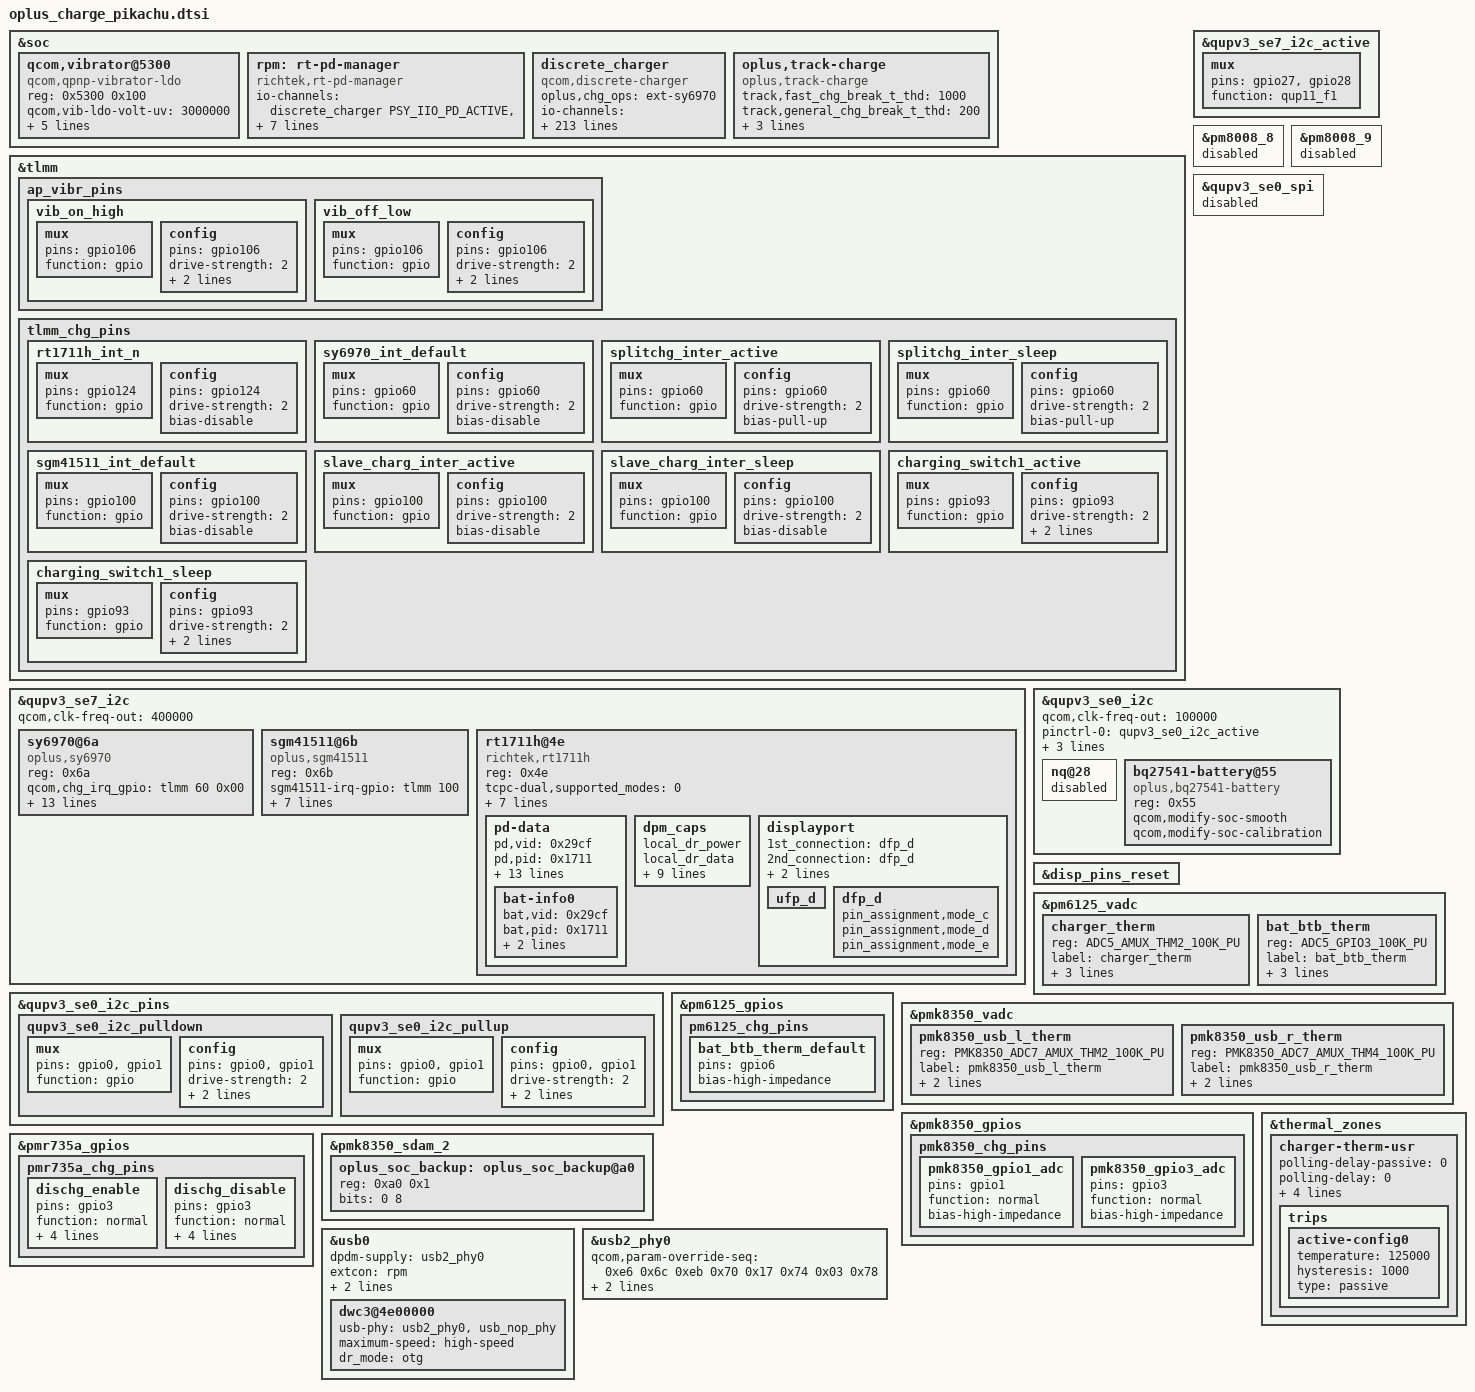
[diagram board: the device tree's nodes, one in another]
#include <dt-bindings/spmi/spmi.h>
#include <dt-bindings/iio/qcom,spmi-vadc.h>
#include <dt-bindings/iio/qti_power_supply_iio.h>

&soc {
	qcom,vibrator@5300 {
		compatible = "qcom,qpnp-vibrator-ldo";
		reg = <0x5300 0x100>;
		qcom,vib-ldo-volt-uv = <3000000>;
		qcom,disable-overdrive;
		qcom,vib-type = <1>;	/*0:ldo 1:gpio*/
		status = "okay";

		qcom,vibrator_switch-gpio = <&tlmm 106 0x00>;
		pinctrl-names = "vib_on_high", "vib_off_low";
		pinctrl-0 = <&vib_on_high>;
		pinctrl-1 = <&vib_off_low >;
	};
};

&tlmm {
	ap_vibr_pins: ap_vibr_pins{
		vib_on_high: vib_on_high{
			mux {
				pins = "gpio106";
				function = "gpio";
			};

			config {
				pins = "gpio106";
				drive-strength = <2>;
				bias-disable;
				output-high;
			};
		};

		vib_off_low: vib_off_low{
			mux {
				pins = "gpio106";
				function = "gpio";
			};

			config {
				pins = "gpio106";
				drive-strength = <2>;
				bias-disable;
				output-high;
			};
		};
	};
};


/* Main charger, slave charger, CC logic I2C */
&qupv3_se7_i2c_active {
        mux {
                pins = "gpio27", "gpio28";
                function = "qup11_f1";
        };
};

&qupv3_se7_i2c {
	status = "okay";
	qcom,clk-freq-out = <400000>;

	sy6970@6a {
		status = "okay";
		compatible = "oplus,sy6970";
		reg = <0x6a>; /*The device operates as a slave device with address 6AH*/

		qcom,chg_irq_gpio = <&tlmm 60 0x00>;
		dpdm-supply = <&usb2_phy0>;
		pinctrl-names = "default",
					"splitchg_inter_active",
					"splitchg_inter_sleep";

		pinctrl-0 = <&sy6970_int_default>;
		pinctrl-1 = <&splitchg_inter_active>;
		pinctrl-2 = <&splitchg_inter_sleep>;

		ti,sy6970,usb-vlim =<4400>;
		ti,sy6970,usb-vreg = <4400>;
		ti,sy6970,usb-ichg = <500>;
		ti,sy6970,precharge-current = <256>;
		ti,sy6970,termination-current = <320>;
		ti,sy6970,charge-detect-enable;
		ti,sy6970,boost-voltage = <5100>;
		ti,sy6970,boost-current = <1400>;

		/*
		 * Charger name
		 * Main charger: primary_chg
		 * Slave charger: secondary_chg
		 */
		charger_name = "primary_chg";
	};

	sgm41511@6b {
        compatible = "oplus,sgm41511";
        reg = <0x6b>; /*The device operates as a slave device with address 6BH*/
		status = "okay";

        sgm41511-irq-gpio = <&tlmm 100 0x00>;
	qcom,set_sgm41511_ovp = <10500>;	/*mv*/
		pinctrl-names = "default",
					"slave_charg_inter_active",
					"slave_charg_inter_sleep",
					"charging_switch1_active",
					"charging_switch1_sleep";
		pinctrl-0 = <&sgm41511_int_default>;
		pinctrl-1 = <&slave_charg_inter_active>;
		pinctrl-2 = <&slave_charg_inter_sleep>;
		pinctrl-3 = <&charging_switch1_active>;
		pinctrl-4 = <&charging_switch1_sleep>;

		/*Pikachu Used as MOS control grid for auxiliary charging and slow power on*/
		qcom,slave_charg_enable-gpio = <&tlmm 93 0x00>;
        };

	rt1711h@4e {
		compatible = "richtek,rt1711h";
		reg = <0x4e>;
		status = "okay";
		tcpc-dual,supported_modes = <0>; /* 0: dfp/ufp, */
						 /* 1: dfp, 2: ufp */
		rt-tcpc,name = "type_c_port0"; /* tcpc_device's name */
		rt-tcpc,role_def = <1>; /* 0: Unknown, 1: SNK, 2: SRC */
					/* 3: DRP, 4: Try.SRC, 5: Try.SNK */
		rt-tcpc,rp_level = <0>; /* 0: Default, 1: 1.5, 2: 3.0 */
		rt-tcpc,vconn_supply  = <1>;  /* 0: Never, 1: Always, */
					      /* 2: EMarkOnly, 3: StartOnly */
		/* rt-tcpc,disable_pe; */
		rt1711pd,intr_gpio = <&tlmm 124 0x0>;
		rt1711pd,intr_gpio_num = <124>;
		pinctrl-names = "default";
		pinctrl-0 = <&rt1711h_int_n>;
		pd-data {
			pd,vid = <0x29cf>;
			pd,pid = <0x1711>;
			pd,source-cap-ext = <0x171129cf 0x00000000 0x00000000
					     0x00000000 0x00000000 0x02000000>;
			pd,mfrs = "RichtekTCPC";

			/*
			 *	VSAFE5V = 0, MAX_POWER = 1, CUSTOM = 2,
			 *	MAX_POWER_LV = 0x21, MAX_POWER_LVIC = 0x31
			 *	MAX_POWER_HV = 0x41, MAX_POWER_HVIC = 0x51
			 */
			pd,charging_policy= <0x31>;

			/*
			 * Fixed 5V, 500 mA <0x00019032>
			 * Fixed 5V, 1A <0x00019064>
			 * Fixed 5V, 2A <0x000190c8>
			 * Fixed 5V, 3A <0x0001912c>
			 * Fixed 9V, 500 mA <0x0002d032>
			 * Fixed 9V, 1A <0x0002d064>
			 * Fixed 9V, 2A <0x0002d0c8>
			 * Fixed 9V, 3A <0x0002d12c>
			 * Variable 5-9V, 1A <0x8642d064>
			 * Variable 5-9V, 2A <0x8642d0c8>
			 * Variable 5-9V, 3A <0x8642d12c>
			 * PPS 3V~5.9V, 3A <0xC0761E3C>
			 */
			pd,source-pdo-size = <1>;
			pd,source-pdo-data = <0x00019032>;
			pd,sink-pdo-size = <1>;
			pd,sink-pdo-data = <0x000190c8>;

			/*
			 * No DP, host + device
			 *	pd,id-vdo-size = <6>;
			 *	pd,id-vdo-data = <0xd14029cf 0x0 0x17110000
						  0x41800000 0x0 0x21800000>;
			 * With DP
			 *	pd,id-vdo-size = <6>;
			 *	pd,id-vdo-data = <0xd54029cf 0x0 0x17110000
						  0x41800000 0x0 0x21800000>;
			 */

			pd,id-vdo-size = <6>;
			pd,id-vdo-data = <0xd14029cf 0x0 0x17110000
					  0x41800000 0x0 0x21800000>;

			bat,nr = <1>;
			pd,country_nr = <0>;

			bat-info0 {
				bat,vid = <0x29cf>;
				bat,pid = <0x1711>;
				bat,mfrs = "bat1";
				bat,design_cap = <3000>;
			};

			//bat-info1 {
			//	bat,vid = <0x8abc>;
			//	bat,pid = <0x5234>;
			//	bat,mfrs = "bat2";
			//	bat,design_cap = <4000>;
			//};

			//country0 {
			//	pd,country_code = <0x5457>;
			//	pd,country_len = <2>; /* max len = 26 */
			//	pd,country_data = <0xff 0xff>;
			//};

			//country1 {
			//	pd,country_code = <0x5553>;
			//	pd,country_len = <3>; /* max len = 26 */
			//	pd,country_data = <0xf1 0xf2 0xf3>;
			//};
		};
		dpm_caps {
			local_dr_power;
			local_dr_data;
			//local_ext_power;
			local_usb_comm;
			//local_usb_suspend;
			//local_high_cap;
			//local_give_back;
			local_no_suspend;
			local_vconn_supply;

			//attemp_discover_cable_dfp;
			attemp_enter_dp_mode;
			attemp_discover_cable;
			attemp_discover_id;
			attemp_discover_svid;

			/* 0: disable, 1: prefer_snk, 2: prefer_src */
			pr_check = <0>;
			//pr_reject_as_source;
			//pr_reject_as_sink;
			//pr_check_gp_source;
			//pr_check_gp_sink;

			/* 0: disable, 1: prefer_ufp, 2: prefer_dfp */
			dr_check = <0>;
			//dr_reject_as_dfp;
			//dr_reject_as_ufp;
		};
		displayport {
			/* connection type = "both", "ufp_d", "dfp_d" */
			1st_connection = "dfp_d";
			2nd_connection = "dfp_d";
			signal,dp_v13;
			//signal,dp_gen2;
			//usbr20_not_used;
			typec,receptacle;
			ufp_d {
				//pin_assignment,mode_a;
				//pin_assignment,mode_b;
				//pin_assignment,mode_c;
				//pin_assignment,mode_d;
				//pin_assignment,mode_e;
			};
			dfp_d {
				//pin_assignment,mode_a;
				//pin_assignment,mode_b;
				pin_assignment,mode_c;
				pin_assignment,mode_d;
				pin_assignment,mode_e;
				//pin_assignment,mode_f;
			};
		};
	};
};

&soc {
	rpm: rt-pd-manager {
		compatible = "richtek,rt-pd-manager";
		#io-channel-cells = <1>;
		io-channels = <&discrete_charger PSY_IIO_PD_ACTIVE>,
			      <&discrete_charger PSY_IIO_PD_USB_SUSPEND_SUPPORTED>,
			      <&discrete_charger PSY_IIO_PD_IN_HARD_RESET>,
			      <&discrete_charger PSY_IIO_PD_CURRENT_MAX>,
			      <&discrete_charger PSY_IIO_PD_VOLTAGE_MIN>,
			      <&discrete_charger PSY_IIO_PD_VOLTAGE_MAX>,
			      <&discrete_charger PSY_IIO_USB_REAL_TYPE>,
			      <&discrete_charger PSY_IIO_PD_SDP>;
		io-channel-names = "pd_active",
				   "pd_usb_suspend_supported",
				   "pd_in_hard_reset",
				   "pd_current_max",
				   "pd_voltage_min",
				   "pd_voltage_max",
				   "real_type",
				   "pd_sdp";
	};
};

&pm8008_8 {
	status = "disabled";
};

&pm8008_9 {
	status = "disabled";
};

&tlmm {
	tlmm_chg_pins: tlmm_chg_pins {
		rt1711h_int_n: rt1711h_int_n {
			mux {
				pins = "gpio124";
				function = "gpio";
			};

			config {
				pins = "gpio124";
				drive-strength = <2>;
				bias-disable;
			};
		};

		/*SY6970*/
		sy6970_int_default: sy6970_int_default {
			mux {
				pins = "gpio60";
				function = "gpio";
			};
			config {
				pins = "gpio60";
				drive-strength = <2>;
				bias-disable;
			};
		};

		/*split_chg*/
		splitchg_inter_active: splitchg_inter_active {
			mux {
				pins = "gpio60";
				function = "gpio";
			};
			config {
				pins = "gpio60";
				drive-strength = <2>;
				bias-pull-up;
			};
		};

		splitchg_inter_sleep: splitchg_inter_sleep {
			mux {
				pins = "gpio60";
				function = "gpio";
			};
			config {
				pins = "gpio60";
				drive-strength = <2>;
				bias-pull-up;
			};
		};

		/*SGM41511*/
		sgm41511_int_default: sgm41511_int_default {
			mux {
				pins = "gpio100";
				function = "gpio";
			};

			config {
				pins = "gpio100";
				drive-strength = <2>;
				bias-disable; /* NO PULL */
			};
		};
		slave_charg_inter_active: slave_charg_inter_active {
			mux {
				pins = "gpio100";
				function = "gpio";
			};

			config {
				pins = "gpio100";
				drive-strength = <2>;
				bias-disable; /* NO PULL */
			};
		};

		slave_charg_inter_sleep: slave_charg_inter_sleep {
			mux {
				pins = "gpio100";
				function = "gpio";
			};

			config {
				pins = "gpio100";
				drive-strength = <2>;
				bias-disable; /* NO PULL */
			};
		};

		charging_switch1_active: charging_switch1_active {
			mux {
				pins = "gpio93";
				function = "gpio";
			};

			config {
				pins = "gpio93";
				drive-strength = <2>;
				bias-disable;
				output-high;
			};
		};

		charging_switch1_sleep: charging_switch1_sleep {
			mux {
				pins = "gpio93";
				function = "gpio";
			};

			config {
				pins = "gpio93";
				drive-strength = <2>;
				bias-disable;
				output-low;
			};
		};
	};
};

&qupv3_se0_spi {
	status = "disabled";
};

&qupv3_se0_i2c_pins {
	qupv3_se0_i2c_pulldown: qupv3_se0_i2c_pulldown {
		mux {
			pins = "gpio0", "gpio1";
			function = "gpio";
		};

		config {
			pins = "gpio0", "gpio1";
			drive-strength = <2>;
			bias-pull-down;
			output-low;
		};
	};

	qupv3_se0_i2c_pullup: qupv3_se0_i2c_pullup {
		mux {
			pins = "gpio0", "gpio1";
			function = "gpio";
		};

		config {
			pins = "gpio0", "gpio1";
			drive-strength = <2>;
			bias-pull-up;
			input-enable;
		};
	};
};

&qupv3_se0_i2c {
	status = "okay";
	qcom,clk-freq-out = <100000>;

	pinctrl-names = "default", "sleep", "pulldown", "pullup";
        pinctrl-0 = <&qupv3_se0_i2c_active>;
        pinctrl-1 = <&qupv3_se0_i2c_sleep>;
        pinctrl-2 = <&qupv3_se0_i2c_pulldown>;
        pinctrl-3 = <&qupv3_se0_i2c_pullup>;

	nq@28 {
		status = "disabled";
	};

	bq27541-battery@55 {
		status = "okay";
		compatible = "oplus,bq27541-battery";
		reg = <0x55>;
		qcom,modify-soc-smooth;
		qcom,modify-soc-calibration;
	};
};

&disp_pins_reset {
	/delete-property/ pins;
	/delete-property/ function;
	/delete-property/ qcom,drive-strength;
	/delete-property/ power-source;
	/delete-property/ bias-disable;
	/delete-property/ output-low;
};

&pm6125_vadc {
	charger_therm {
		reg = <ADC5_AMUX_THM2_100K_PU>;
		label = "charger_therm";
		qcom,ratiometric;
		qcom,hw-settle-time = <200>;
		qcom,pre-scaling = <1 1>;
	};

	bat_btb_therm {
		reg = <ADC5_GPIO3_100K_PU>;
		label = "bat_btb_therm";
		qcom,ratiometric;
		qcom,hw-settle-time = <200>;
		qcom,pre-scaling = <1 1>;
	};
};

&pm6125_gpios {
	pm6125_chg_pins: pm6125_chg_pins {
		bat_btb_therm_default: bat_btb_therm_default {
			pins = "gpio6";
			bias-high-impedance;
		};
	};
};

&pmk8350_vadc {
	pmk8350_usb_l_therm: pmk8350_usb_l_therm {
		reg = <PMK8350_ADC7_AMUX_THM2_100K_PU>;
		label = "pmk8350_usb_l_therm";
		qcom,pre-scaling = <1 1>;
		qcom,scale-fn-type = <ADC_SCALE_HW_CALIB_DEFAULT>;
	};

	pmk8350_usb_r_therm: pmk8350_usb_r_therm {
		reg = <PMK8350_ADC7_AMUX_THM4_100K_PU>;
		label = "pmk8350_usb_r_therm";
		qcom,pre-scaling = <1 1>;
		qcom,scale-fn-type = <ADC_SCALE_HW_CALIB_DEFAULT>;
	};
};

&pmk8350_gpios {
	pmk8350_chg_pins: pmk8350_chg_pins {
		pmk8350_gpio1_adc: pmk8350_gpio1_adc {
			pins = "gpio1"; /* GPIO 1 */
			function = "normal"; /* normal */
			bias-high-impedance; /* DISABLE GPIO1 for ADC*/
		};

		pmk8350_gpio3_adc: pmk8350_gpio3_adc {
			pins = "gpio3"; /* GPIO 3 */
			function = "normal"; /* normal */
			bias-high-impedance; /* DISABLE GPIO3 for ADC*/
		};
	};
};

&pmr735a_gpios {
	pmr735a_chg_pins: pmr735a_chg_pins {
		dischg_enable: dischg_enable {
			pins = "gpio3";
			function = "normal";
			bias-disable;
			power-source = <0>;
			output-high;
			qcom,drive-strength = <3>;
		};

		dischg_disable: dischg_disable {
			pins = "gpio3";
			function = "normal";
			bias-disable;
			power-source = <0>;
			output-low;
			qcom,drive-strength = <3>;
		};
	};
};

&pmk8350_sdam_2 {
	oplus_soc_backup: oplus_soc_backup@a0 {
		reg = <0xa0 0x1>;
		bits = <0 8>;
	};
};

&soc {
	discrete_charger: discrete_charger {
		compatible = "qcom,discrete-charger";
		status = "okay";

		oplus,chg_ops = "ext-sy6970";
		#io-channel-cells = <1>;
		io-channels = <&pmk8350_vadc PMK8350_ADC7_AMUX_THM2_100K_PU>,
					  <&pmk8350_vadc PMK8350_ADC7_AMUX_THM4_100K_PU>,
					  <&pm6125_vadc ADC5_GPIO3_100K_PU>,
					  <&pm6125_vadc ADC5_AMUX_THM2_100K_PU>;
		io-channel-names = "usbtemp_r_v_chan",
						   "usbtemp_l_v_chan",
						   "usbbtb_temp_chan",
						   "batbtb_temp_chan";

		nvmem-cell-names = "oplus_soc_backup";
		nvmem-cells = <&oplus_soc_backup>;

		pinctrl-names = "default",
					"dischg_enable",
					"dischg_disable",
					"2uart_active",
					"2uart_sleep";

		pinctrl-0 = <&bat_btb_therm_default
					&pmk8350_gpio1_adc
					&pmk8350_gpio3_adc
					>;
		pinctrl-1 = <&dischg_enable>;
		pinctrl-2 = <&dischg_disable>;
		pinctrl-3 = <&qupv3_se9_2uart_active>;
		pinctrl-4 = <&qupv3_se9_2uart_sleep>;

		//for oplus chg framework
		qcom,tbatt_pdqc_to_5v_thr = <420>;
		qcom,input_current_charger_ma = <2000>;
		qcom,qc_input_current_charger_ma = <2000>;
		qcom,pd_input_current_charger_ma = <2000>;
		qcom,input_current_cdp_ma = <1500>;
		qcom,input_current_usb_ma = <500>;
		qcom,input_current_led_ma = <1200>;
		qcom,input_current_led_ma_forcmcc = <500>;
		qcom,input_current_camera_ma = <1200>;
		qcom,input_current_calling_ma = <1500>;

		qcom,input_current_led_ma_high = <1200>;
		qcom,input_current_led_ma_warm = <1500>;
		qcom,input_current_led_ma_normal = <2000>;

		qcom,led_high_bat_decidegc = <370>;
		qcom,led_warm_bat_decidegc = <350>;

		qcom,iterm_disabled = <0>;
		qcom,iterm_ma = <230>;
		qcom,recharge-mv = <100>;

		qcom,batt_capacity_mah = <4500>; /*typical capacity*/
		//qcom,batt_capacity_mah = <3900>; /*rated capacity*/

		qcom,removed_bat_decidegc = <190>;  /* < -19C */

		qcom,cold_bat_decidegc = <100>;  /* -10C ~ 0C */
		qcom,temp_cold_vfloat_mv = <4435>;
		qcom,temp_cold_fastchg_current_ma_high = <1100>;
		qcom,temp_cold_fastchg_current_ma_low = <1100>;
		qcom,temp_cold_fastchg_current_ma = <1100>;
		qcom,pd_temp_cold_fastchg_current_ma_high = <1100>;
		qcom,pd_temp_cold_fastchg_current_ma_low = <1100>;
		qcom,qc_temp_cold_fastchg_current_ma_high = <1100>;
		qcom,qc_temp_cold_fastchg_current_ma_low = <1100>;

		qcom,little_cold_bat_decidegc = <0>;	/* 0C ~ 5C */
		qcom,temp_little_cold_vfloat_mv = <4435>;
		qcom,temp_little_cold_fastchg_current_ma_high = <2200>;
		qcom,temp_little_cold_fastchg_current_ma_low = <2200>;
		qcom,temp_little_cold_fastchg_current_ma = <2200>;
		qcom,qc_temp_little_cold_fastchg_current_ma_high = <3400>;
		qcom,qc_temp_little_cold_fastchg_current_ma_low = <2860>;
		qcom,pd_temp_little_cold_fastchg_current_ma_high = <3400>;
		qcom,pd_temp_little_cold_fastchg_current_ma_low = <2860>;

		qcom,cool_bat_decidegc = <50>;	/* 5C ~ 12C */
		qcom,temp_cool_vfloat_mv = <4435>;
		qcom,temp_cool_fastchg_current_ma_high = <2200>;
		qcom,temp_cool_fastchg_current_ma_low = <2200>;
		qcom,qc_temp_cool_fastchg_current_ma_high = <3400>;
		qcom,qc_temp_cool_fastchg_current_ma_low = <3400>;
		qcom,pd_temp_cool_fastchg_current_ma_high = <3400>;
		qcom,pd_temp_cool_fastchg_current_ma_low = <3400>;

		qcom,little_cool_bat_decidegc = <120>;	/* 12C ~ 16C */
		qcom,temp_little_cool_vfloat_mv = <4435>;
		qcom,temp_little_cool_fastchg_current_ma = <2200>;
		qcom,temp_little_cool_usbchg_current_ma = <550>;
		qcom,temp_little_cool_fastchg_current_ma_high = <2200>;
		qcom,temp_little_cool_fastchg_current_ma_low = <2200>;
		qcom,qc_temp_little_cool_fastchg_current_ma = <3400>;
		qcom,qc_temp_little_cool_fastchg_current_ma_high = <3400>;
		qcom,qc_temp_little_cool_fastchg_current_ma_low = <3400>;
		qcom,pd_temp_little_cool_fastchg_current_ma = <3400>;
		qcom,pd_temp_little_cool_fastchg_current_ma_high = <3400>;
		qcom,pd_temp_little_cool_fastchg_current_ma_low = <3400>;

		qcom,normal_bat_decidegc = <160>;	/* 16C ~ 45C */
		qcom,temp_normal_fastchg_current_ma = <2200>;
		qcom,temp_normal_vfloat_mv = <4435>;
		qcom,pd_temp_normal_fastchg_current_ma = <3400>;
		qcom,qc_temp_normal_fastchg_current_ma = <3400>;

		qcom,warm_bat_decidegc = <450>;		/* 45C ~ 53C */ /*8pin Bat Vooc project need add 3 degree C*/
		qcom,temp_warm_vfloat_mv = <4130>;
		qcom,temp_warm_fastchg_current_ma = <2200>;
		qcom,temp_warm_fastchg_current_ma_led_on = <1000>;
		qcom,qc_temp_warm_fastchg_current_ma = <2420>;
		qcom,pd_temp_warm_fastchg_current_ma = <2420>;

		qcom,hot_bat_decidegc = <530>;  /* > 53C */

		qcom,non_standard_vfloat_mv = <3980>;
		qcom,non_standard_fastchg_current_ma = <500>;

		qcom,short_c_bat_cv_mv = <4330>;
		qcom,short_c_bat_vfloat_mv = <3800>;
		qcom,short_c_bat_fastchg_current_ma = <512>;
		qcom,short_c_bat_vfloat_sw_limit = <3750>;

		qcom,cold_vfloat_sw_limit = <4385>;
		qcom,little_cold_vfloat_sw_limit = <4385>;
		qcom,cool_vfloat_sw_limit = <4385>;
		qcom,little_cool_vfloat_sw_limit = <4385>;
		qcom,normal_vfloat_sw_limit = <4385>;
		qcom,warm_vfloat_sw_limit = <4080>;
		qcom,non_standard_vfloat_sw_limit = <3930>;

		qcom,normal_phase1_bat_decidegc = <160>;       /* 16C ~ 22C */
		qcom,temp_normal_phase1_vfloat_mv = <4435>;
		qcom,temp_normal_phase1_fastchg_current_ma = <3400>;

		qcom,normal_phase2_bat_decidegc = <220>;       /* 22C ~ 33C */
		qcom,temp_normal_phase2_vfloat_mv = <4435>;
		qcom,temp_normal_phase2_fastchg_current_ma_high = <3400>;
		qcom,temp_normal_phase2_fastchg_current_ma_low = <3400>;

		qcom,normal_phase3_bat_decidegc = <330>;       /* 33 ~ 36C */
		qcom,temp_normal_phase3_vfloat_mv = <4435>;
		qcom,temp_normal_phase3_fastchg_current_ma_high = <3400>;
		qcom,temp_normal_phase3_fastchg_current_ma_low = <3400>;

		qcom,normal_phase4_bat_decidegc = <360>;       /* 36C ~ 39C */
		qcom,temp_normal_phase4_vfloat_mv = <4435>;
		qcom,temp_normal_phase4_fastchg_current_ma_high = <3400>;
		qcom,temp_normal_phase4_fastchg_current_ma_low = <3400>;

		qcom,normal_phase5_bat_decidegc = <390>;       /* 39C ~ 42C */
		qcom,temp_normal_phase5_vfloat_mv = <4435>;
		qcom,temp_normal_phase5_fastchg_current_ma = <3400>;

		qcom,normal_phase6_bat_decidegc = <420>;       /* 42C ~ 45C */
		qcom,temp_normal_phase6_vfloat_mv = <4435>;
		qcom,temp_normal_phase6_fastchg_current_ma = <3400>;

		qcom,max_chg_time_sec = <64800>;  //39600S
		qcom,charger_hv_thr = <10000>;
		qcom,charger_recv_thr = <98000>;
		qcom,charger_lv_thr = <3400>;
		qcom,vbatt_full_thr = <4435>;
		qcom,vbatt_hv_thr = <4600>;

		qcom,vfloat_step_mv = <8>;
		qcom,non_standard_vfloat_over_sw_limit = <3990>;
		qcom,cold_vfloat_over_sw_limit = <4445>;
		qcom,little_cold_vfloat_over_sw_limit = <4445>;
		qcom,cool_vfloat_over_sw_limit = <4445>;
		qcom,little_cool_vfloat_over_sw_limit = <4445>;
		qcom,normal_vfloat_over_sw_limit = <4445>;
		qcom,warm_vfloat_over_sw_limit = <4140>;

		qcom,vbatt_power_off = <3300>;
		qcom,vbatt_soc_1 = <3410>;
		qcom,vooc_project = <0>;
		qcom,vbatt_num = <1>;

		qcom,normal_vterm_hw_inc = <18>;
		qcom,non_normal_vterm_hw_inc = <18>;
		qcom,usbtemp_batttemp_gap = <12>;

		qcom,ff1_normal_fastchg_ma = <1088>;
		qcom,ffc2_normal_fastchg_ma = <780>;/*16C~35c*/
		qcom,ffc2_temp_warm_decidegc = <350>;
		qcom,ffc2_warm_fastchg_ma = <840>;/*35C~40c*/
		qcom,ffc2_temp_high_decidegc = <400>;
		qcom,ffc2_temp_low_decidegc = <120>;
		qcom,ff1_exit_step_ma = <488>;
		qcom,ff1_warm_exit_step_ma = <418>;
		qcom,ffc2_exit_step_ma = <180>;
		qcom,ffc2_warm_exit_step_ma = <170>;

		qcom,ffc_normal_vfloat_sw_limit = <4430>;
		qcom,ffc_temp_normal_vfloat_mv = <4500>;
		qcom,ffc_normal_vfloat_over_sw_limit = <4500>;

		qcom,default_iterm_ma = <230>;
		qcom,default_temp_normal_fastchg_current_ma = <2200>;
		qcom,default_normal_vfloat_sw_limit = <4380>;
		qcom,default_temp_normal_vfloat_mv = <4435>;
		qcom,default_normal_vfloat_over_sw_limit = <4445>;

		//for 2nd chip:
		qcom,iterm_ma_2nd = <300>;
		qcom,recharge-mv_2nd = <121>;

		qcom,temp_little_cold_vfloat_mv_2nd = <4391>;	/* 0C ~ 5C */
		qcom,temp_cool_vfloat_mv_2nd = <4391>;	/* 5C ~ 12C */
		qcom,temp_little_cool_vfloat_mv_2nd = <4391>;	/* 12C ~ 16C */
		qcom,temp_normal_vfloat_mv_2nd = <4391>;	/* 16C ~ 45C */

		qcom,little_cold_vfloat_over_sw_limit_2nd = <4395>;
		qcom,cool_vfloat_over_sw_limit_2nd = <4395>;
		qcom,little_cool_vfloat_over_sw_limit_2nd = <4395>;
		qcom,normal_vfloat_over_sw_limit_2nd = <4395>;

		qcom,default_iterm_ma_2nd = <300>;
		qcom,default_temp_normal_vfloat_mv_2nd = <4391>;
		qcom,default_normal_vfloat_over_sw_limit_2nd = <4395>;

		//for control:
		qcom,dual_charger_support;
		//qcom,suspend_after_full;
		qcom,check_batt_full_by_sw;
		qcom,smart_charging_screenoff;
		qcom,external_gauge;
		qcom,chg_ctrl_by_calling;
		qcom,chg_ctrl_by_lcd;
		qcom,chg_ctrl_by_camera;
		qcom,sw_vfloat_over_protect_enable;

		//for PD9V or QC9V
		qcom,vbatt_pdqc_to_5v_thr = <4435>;
		qcom,vbatt_pdqc_to_9v_thr = <4435>;
		qcom,slave_pct = <40>;
		qcom,slave_chg_enable_ma = <2100>;
		qcom,slave_chg_disable_ma = <1800>;

		//GPIO config:
		qcom,dischg-gpio = <&pmr735a_gpios 3 0x00>;
	};
};

&usb0 {
	dpdm-supply = <&usb2_phy0>;
	extcon = <&rpm>;
	#io-channel-cells = <1>;
	io-channels = <&discrete_charger PSY_IIO_USB_REAL_TYPE>;
	io-channel-names = "chg_type";
	dwc3@4e00000 {
		usb-phy = <&usb2_phy0>, <&usb_nop_phy>;
		maximum-speed = "high-speed";
		dr_mode = "otg";
	};
};

&usb2_phy0 {
	qcom,param-override-seq =
		<0xe6 0x6c	/* override_x0 */
		 0xeb 0x70	/* override_x1 */
		 0x17 0x74	/* override x2 */
		 0x03 0x78>;	/* override x3 */
	qcom,param-override-host-seq =
		<0xe6 0x6c	/* override_x0 */
		 0xeb 0x70	/* override_x1 */
		 0x17 0x74	/* override x2 */
		 0x03 0x78>;	/* override x3 */
};

&thermal_zones {
	charger-therm-usr {
		polling-delay-passive = <0>;
		polling-delay = <0>;
		thermal-governor = "user_space";
		thermal-sensors = <&pm6125_adc_tm ADC5_AMUX_THM2_100K_PU>;
		wake-capable-sensor;
		trips {
			active-config0 {
				temperature = <125000>;
				hysteresis = <1000>;
				type = "passive";
			};
		};
	};
};

&soc {
	oplus,track-charge {
		compatible = "oplus,track-charge";
		track,fast_chg_break_t_thd = <1000>;
		track,general_chg_break_t_thd = <200>;
		track,voocphy_type = <0>;
		track,wired_max_power = <18000>;
		track,wired_fast_chg_scheme = <6>;
	};
};
